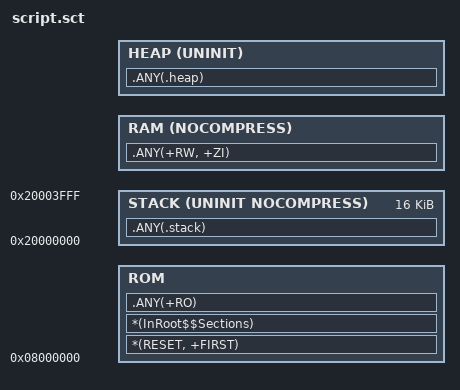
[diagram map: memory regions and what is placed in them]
/*******************************************************************************
@file     stm32l1xx.sct
@author   Rajmund Szymanski
@date     11.12.2019
@brief    Scatter file for STM32L152RB device with 128KB FLASH and 16KB RAM
*******************************************************************************/

FLASH 0x08000000 0x00020000
{
	ROM +0
	{
		*(RESET, +FIRST)
		*(InRoot$$Sections)
		.ANY(+RO)
	}

	STACK 0x20000000 UNINIT NOCOMPRESS 0x00004000
	{
		.ANY(.stack)
	}

	RAM ALIGNEXPR(+0, 8) NOCOMPRESS
	{
		.ANY(+RW, +ZI)
	}

	HEAP ALIGNEXPR(+0, 8) UNINIT
	{
		.ANY(.heap)
	}
}
